# STM32F40x register map
File version: 1.5
CPU: CM4 r1p1, little endian, no MPU, FPU, VTOR, 4 interrupt priority bits
Registers are 32-bit, read-write, reset 0x0 unless marked. A register's access mark holds for its fields unless they carry their own. Offsets are from the block's base; [hi:lo] are bit positions.

## TIM10 — General-purpose-timers
Base 0x40014400
Same registers: TIM13 0x40001C00, TIM14 0x40002000
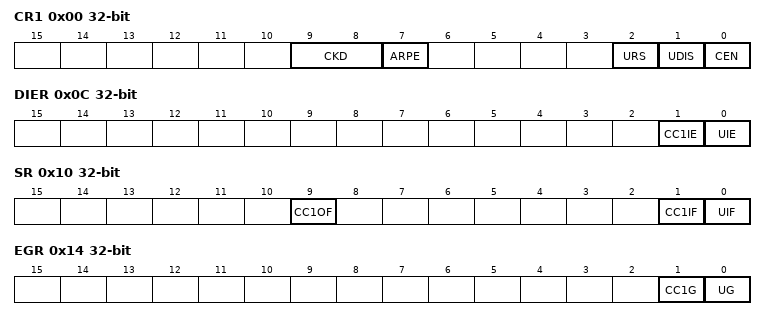
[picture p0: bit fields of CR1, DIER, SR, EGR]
0x00 CR1 — control register 1
  [9:8] CKD — Clock division
  [7] ARPE — Auto-reload preload enable
  [2] URS — Update request source
  [1] UDIS — Update disable
  [0] CEN — Counter enable
0x0C DIER — DMA/Interrupt enable register
  [1] CC1IE — Capture/Compare 1 interrupt enable
  [0] UIE — Update interrupt enable
0x10 SR — status register
  [9] CC1OF — Capture/Compare 1 overcapture flag
  [1] CC1IF — Capture/compare 1 interrupt flag
  [0] UIF — Update interrupt flag
0x14 EGR wo — event generation register
  [1] CC1G — Capture/compare 1 generation
  [0] UG — Update generation
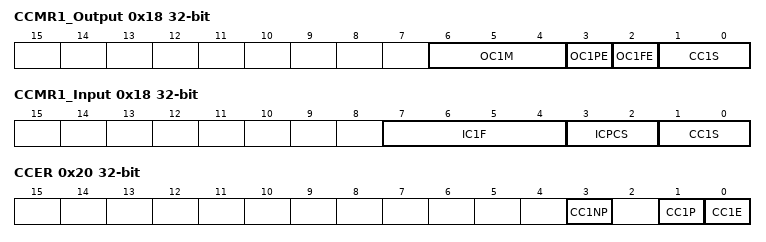
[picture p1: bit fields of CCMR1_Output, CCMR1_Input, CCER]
0x18 CCMR1_Output — capture/compare mode register 1 (output mode)
  [6:4] OC1M — Output Compare 1 mode
  [3] OC1PE — Output Compare 1 preload enable
  [2] OC1FE — Output Compare 1 fast enable
  [1:0] CC1S — Capture/Compare 1 selection
0x18 CCMR1_Input (alternate view of CCMR1_Output) — capture/compare mode register 1 (input mode)
  [7:4] IC1F — Input capture 1 filter
  [3:2] ICPCS — Input capture 1 prescaler
  [1:0] CC1S — Capture/Compare 1 selection
0x20 CCER — capture/compare enable register
  [3] CC1NP — Capture/Compare 1 output Polarity
  [1] CC1P — Capture/Compare 1 output Polarity
  [0] CC1E — Capture/Compare 1 output enable
0x24 CNT — counter
  [15:0] CNT — counter value
0x28 PSC — prescaler
  [15:0] PSC — Prescaler value
0x2C ARR — auto-reload register
  [15:0] ARR — Auto-reload value
0x34 CCR1 — capture/compare register 1
  [15:0] CCR1 — Capture/Compare 1 value

## TIM11 — General-purpose-timers
Base 0x40014800
Registers as TIM10; these are added or differ:
0x50 OR — option register
  [1:0] RMP — Input 1 remapping capability

## TIM6 — Basic timers
Base 0x40001000
Same registers: TIM7 0x40001400
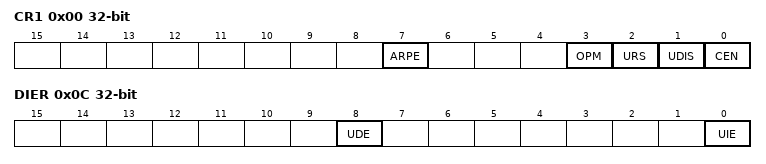
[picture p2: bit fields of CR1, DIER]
0x00 CR1 — control register 1
  [7] ARPE — Auto-reload preload enable
  [3] OPM — One-pulse mode
    0=Continuous (Counter is not stopped at update event); 1=OnePulse (Counter stops counting at the next update event (clearing the CEN bit))
  [2] URS — Update request source
  [1] UDIS — Update disable
  [0] CEN — Counter enable
    0=Disabled (Counter disabled); 1=Enabled (Counter enabled)
0x04 CR2 — control register 2
  [6:4] MMS — Master mode selection
0x0C DIER — DMA/Interrupt enable register
  [8] UDE — Update DMA request enable
  [0] UIE — Update interrupt enable
    0=Disabled (Clock disabled); 1=Enabled (Clock enabled)
0x10 SR — status register
  [0] UIF — Update interrupt flag
    on read: 0=No update occurred; 1=Pending (Update interrupt pending) | on write: 0=Clears the update interrupt flag
0x14 EGR wo — event generation register
  [0] UG — Update generation
0x24 CNT — counter
  [15:0] CNT — Low counter value
0x28 PSC — prescaler
  [15:0] PSC — Prescaler value
0x2C ARR — auto-reload register
  [15:0] ARR — Low Auto-reload value

## Ethernet_MAC — Ethernet: media access control (MAC)
Base 0x40028000
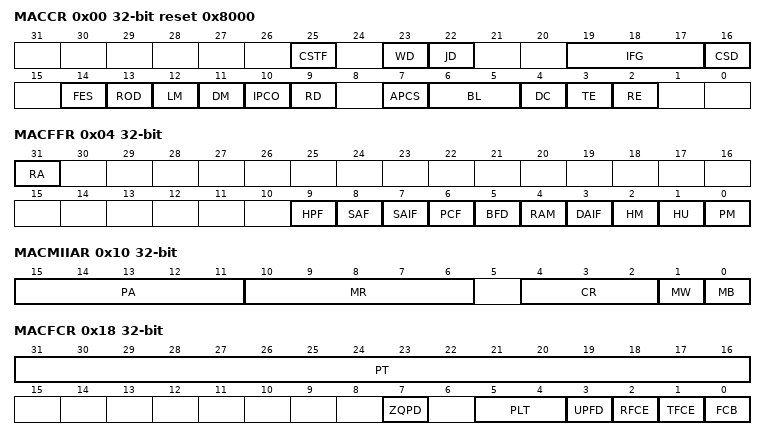
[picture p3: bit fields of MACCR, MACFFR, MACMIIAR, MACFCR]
0x00 MACCR reset 0x8000 — Ethernet MAC configuration register
  [25] CSTF, [23] WD, [22] JD, [19:17] IFG, [16] CSD, [14] FES, [13] ROD, [12] LM, [11] DM, [10] IPCO, [9] RD, [7] APCS, [6:5] BL, [4] DC, [3] TE, [2] RE
0x04 MACFFR — Ethernet MAC frame filter register
  [31] RA, [9] HPF, [8] SAF, [7] SAIF, [6] PCF, [5] BFD, [4] RAM, [3] DAIF, [2] HM, [1] HU, [0] PM
0x08 MACHTHR — Ethernet MAC hash table high register
  [31:0] HTH
0x0C MACHTLR — Ethernet MAC hash table low register
  [31:0] HTL
0x10 MACMIIAR — Ethernet MAC MII address register
  [15:11] PA, [10:6] MR, [4:2] CR, [1] MW, [0] MB
0x14 MACMIIDR — Ethernet MAC MII data register
  [15:0] TD
0x18 MACFCR — Ethernet MAC flow control register
  [31:16] PT, [7] ZQPD, [5:4] PLT, [3] UPFD, [2] RFCE, [1] TFCE, [0] FCB
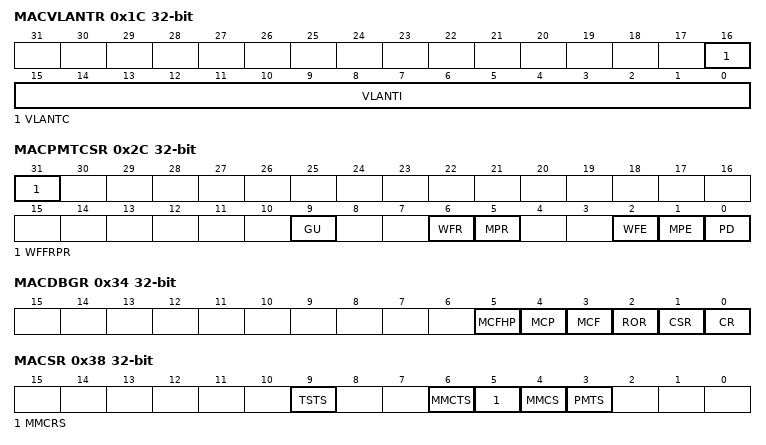
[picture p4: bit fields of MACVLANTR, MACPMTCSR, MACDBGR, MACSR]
0x1C MACVLANTR — Ethernet MAC VLAN tag register
  [16] VLANTC, [15:0] VLANTI
0x2C MACPMTCSR — Ethernet MAC PMT control and status register
  [31] WFFRPR, [9] GU, [6] WFR, [5] MPR, [2] WFE, [1] MPE, [0] PD
0x34 MACDBGR ro — Ethernet MAC debug register
  [5] MCFHP, [4] MCP, [3] MCF, [2] ROR, [1] CSR, [0] CR
0x38 MACSR access per field — Ethernet MAC interrupt status register
  [9] TSTS rw, [6] MMCTS ro, [5] MMCRS ro, [4] MMCS ro, [3] PMTS ro
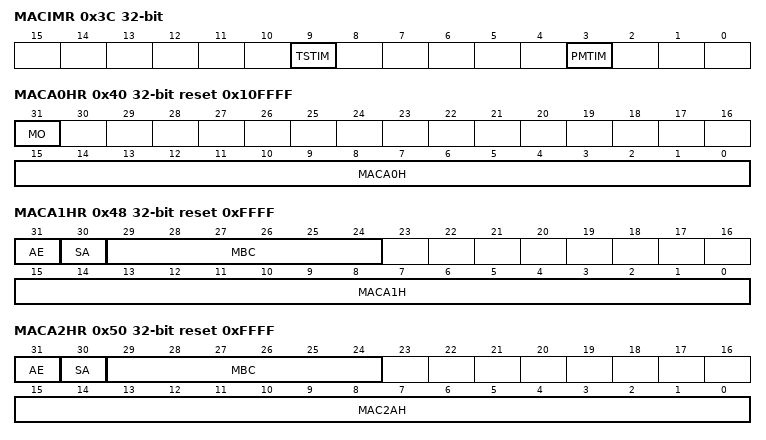
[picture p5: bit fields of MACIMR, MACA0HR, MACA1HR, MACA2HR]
0x3C MACIMR — Ethernet MAC interrupt mask register
  [9] TSTIM, [3] PMTIM
0x40 MACA0HR access per field reset 0x10FFFF — Ethernet MAC address 0 high register
  [31] MO ro — Always 1
  [15:0] MACA0H rw — MAC address0 high
0x44 MACA0LR reset 0xFFFFFFFF — Ethernet MAC address 0 low register
  [31:0] MACA0L — 0
0x48 MACA1HR reset 0xFFFF — Ethernet MAC address 1 high register
  [31] AE, [30] SA, [29:24] MBC, [15:0] MACA1H
0x4C MACA1LR reset 0xFFFFFFFF — Ethernet MAC address1 low register
0x50 MACA2HR reset 0xFFFF — Ethernet MAC address 2 high register
  [31] AE, [30] SA, [29:24] MBC, [15:0] MAC2AH
0x54 MACA2LR reset 0xFFFFFFFF — Ethernet MAC address 2 low register
  [30:0] MACA2L
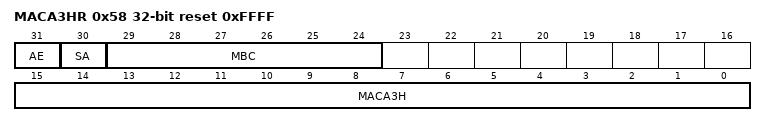
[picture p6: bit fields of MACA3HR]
0x58 MACA3HR reset 0xFFFF — Ethernet MAC address 3 high register
  [31] AE, [30] SA, [29:24] MBC, [15:0] MACA3H
0x5C MACA3LR reset 0xFFFFFFFF — Ethernet MAC address 3 low register
  [31:0] MBCA3L
